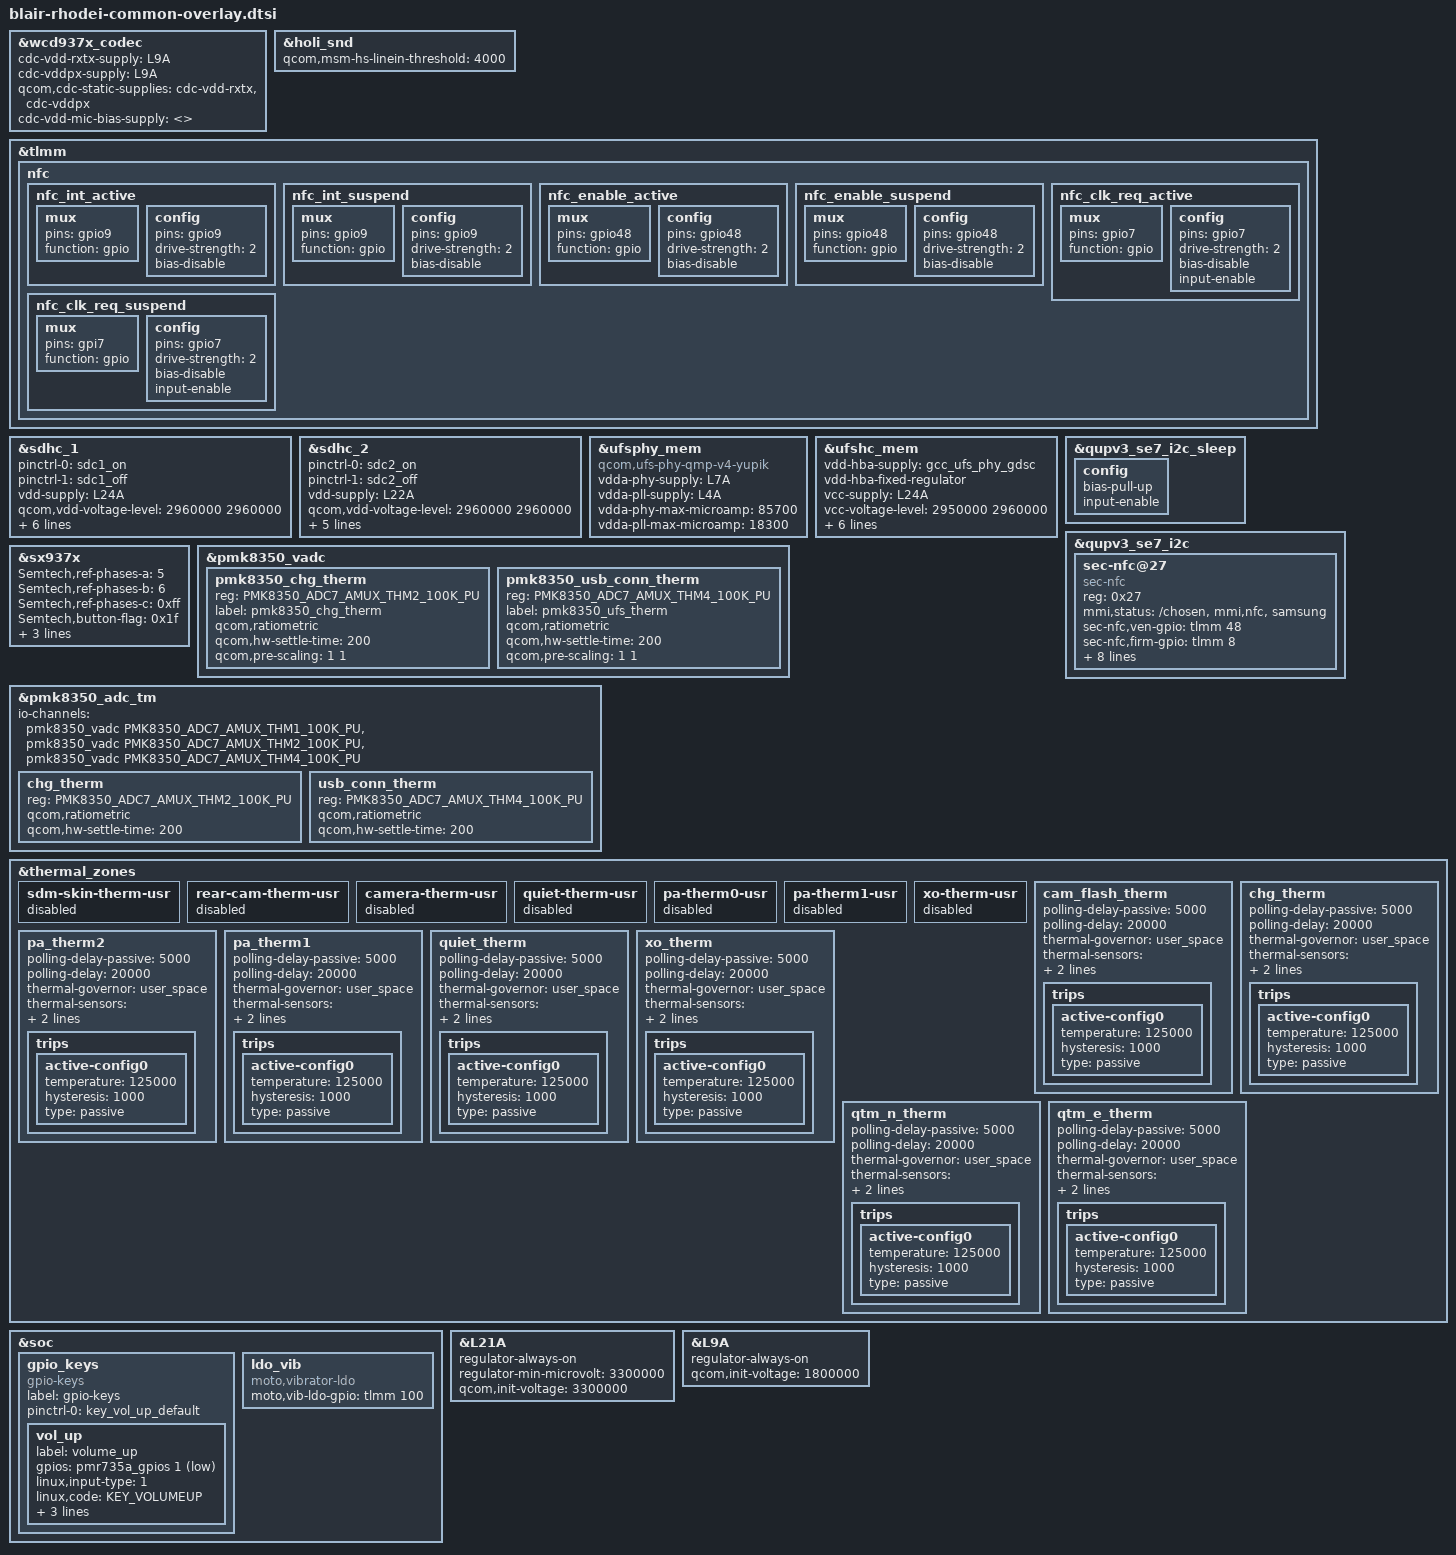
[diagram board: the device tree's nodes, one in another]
/* Copyright (c) 2021, The Linux Foundation. All rights reserved.
 *
 * This program is free software; you can redistribute it and/or modify
 * it under the terms of the GNU General Public License version 2 and
 * only version 2 as published by the Free Software Foundation.
 *
 * This program is distributed in the hope that it will be useful,
 * but WITHOUT ANY WARRANTY; without even the implied warranty of
 * MERCHANTABILITY or FITNESS FOR A PARTICULAR PURPOSE.  See the
 * GNU General Public License for more details.
 */
#include "blair-nopmi-moto-common-overlay.dtsi"

#include "holi-audio-wcd9370-aw882xx-acf-dual-overlay.dtsi"
#include <dt-bindings/gpio/gpio.h>
#include <dt-bindings/input/linux-event-codes.h>
#include "holi-pmic-overlay-pm6125.dtsi"
#include "holi-thermal-overlay-pm6125.dtsi"
#include "display/holi-sde-display-mtp-pm6125.dtsi"
#include "display/blair-sde-display-mtp.dtsi"
#include "rhodei-fps-overlay.dtsi"
#include "rhodei-display.dtsi"
#include "rhodei-touchscreen.dtsi"
#include "camera-legacy/rhodei/blair-camera-sensor-mot-rhodei-overlay.dtsi"
#include "rhodei-wl2868c.dtsi"
#include "discrete_charging_rhodei.dtsi"
#include "moto_therm_sys_temp.dtsi"

&wcd937x_codec {
	cdc-vdd-rxtx-supply = <&L9A>;
	cdc-vddpx-supply = <&L9A>;
	qcom,cdc-static-supplies = "cdc-vdd-rxtx",
				   "cdc-vddpx";
	/*
	 * Overriding cdc-vdd-mic-bias-supply to dummy value
	 * to avoid compilation errors as BOB is not definied
	 * for pm6125
	 */
	cdc-vdd-mic-bias-supply = <>;
};

&holi_snd {
	qcom,msm-hs-linein-threshold = <4000>;
};

&tlmm {
	nfc {
		nfc_int_active: nfc_int_active {
			/* active state */
			mux {
				/* GPIO 9: NFC Read Interrupt */
				pins = "gpio9";
				function = "gpio";
			};

			config {
				pins = "gpio9";
				drive-strength = <2>; /* 2 MA */
				bias-disable;
			};
		};

		nfc_int_suspend: nfc_int_suspend {
			/* sleep state */
			mux {
				/* GPIO 9: NFC Read Interrupt */
				pins = "gpio9";
				function = "gpio";
			};

			config {
				pins = "gpio9";
				drive-strength = <2>; /* 2 MA */
				bias-disable;
			};
		};

		nfc_enable_active: nfc_enable_active {
			mux {
				pins = "gpio48";
				function = "gpio";
			};

			config {
				pins = "gpio48";
				drive-strength = <2>; /* 2 MA */
				bias-disable;
			};
		};

		nfc_enable_suspend: nfc_enable_suspend {
			mux {
				pins = "gpio48";
				function = "gpio";
			};

			config {
				pins = "gpio48";
				drive-strength = <2>; /* 2 MA */
				bias-disable;
			};
		};


		nfc_clk_req_active: nfc_clk_req_active {
			/* active state */
			mux {
				/* GPIO 7: NFC CLK Req*/
				pins = "gpio7";
				function = "gpio";
			};

			config {
				pins = "gpio7";
				drive-strength = <2>; /* 2 MA */
				bias-disable;
				input-enable;
			};
		};

		nfc_clk_req_suspend: nfc_clk_req_suspend {
			/* sleep state */
			mux {
				/* GPIO 7: NFC CLK Req */
				pins = "gpi7";
				function = "gpio";
			};

			config {
				pins = "gpio7";
				drive-strength = <2>; /* 2 MA */
				bias-disable;
				input-enable;
			};
		};
	};
};

/* Dummy LDO reference */
&sdhc_1 {
	status = "ok";

	pinctrl-names = "default", "sleep";
	pinctrl-0 = <&sdc1_on>;
	pinctrl-1 = <&sdc1_off>;

	vdd-supply = <&L24A>;
	qcom,vdd-voltage-level = <2960000 2960000>;
	qcom,vdd-current-level = <0 570000>;

	vdd-io-supply = <&L11A>;
	qcom,vdd-io-always-on;
	qcom,vdd-io-lpm-sup;
	qcom,vdd-io-voltage-level = <1800000 1800000>;
	qcom,vdd-io-current-level = <0 325000>;
};

&sdhc_2 {
	status = "ok";

	pinctrl-names = "default", "sleep";
	pinctrl-0 = <&sdc2_on>;
	pinctrl-1 = <&sdc2_off>;

	vdd-supply = <&L22A>;
	qcom,vdd-voltage-level = <2960000 2960000>;
	qcom,vdd-current-level = <0 800000>;

	vdd-io-supply = <&L5A>;
	qcom,vdd-io-voltage-level = <1800000 2960000>;
	qcom,vdd-io-current-level = <0 22000>;

	cd-gpios = <&tlmm 94 GPIO_ACTIVE_HIGH>;
};

&ufsphy_mem {
		compatible = "qcom,ufs-phy-qmp-v4-yupik";

		vdda-phy-supply = <&L7A>;
		vdda-pll-supply = <&L4A>;
		vdda-phy-max-microamp = <85700>;
		vdda-pll-max-microamp = <18300>;

		status = "ok";
};

&ufshc_mem {
		vdd-hba-supply = <&gcc_ufs_phy_gdsc>;
		vdd-hba-fixed-regulator;

		vcc-supply = <&L24A>;
		vcc-voltage-level = <2950000 2960000>;
		vcc-max-microamp = <800000>;

		vccq2-supply = <&L11A>;
		vccq2-max-microamp = <800000>;
		vccq2-voltage-level = <1800000 1800000>;

		qcom,vddp-ref-clk-supply = <&L4A>;
		qcom,vddp-ref-clk-max-microamp = <100>;

		status = "ok";
};

&qupv3_se7_i2c_sleep {
    config {
        /delete-property/ bias-disable;
        bias-pull-up;
        input-enable;
    };
};

&qupv3_se7_i2c {
	status = "ok";
	#address-cells = <1>;
	#size-cells = <0>;
	sec-nfc@27 {
		compatible = "sec-nfc";
		reg = <0x27>;
		mmi,status = "/chosen", "mmi,nfc", "samsung";
		sec-nfc,ven-gpio = <&tlmm 48 0x00>;
		sec-nfc,firm-gpio = <&tlmm 8 0x00>;
		sec-nfc,irq-gpio = <&tlmm 9 0x00>;
		sec-nfc,clk_req-gpio = <&tlmm 7 0x00>;
		interrupt-parent = <&tlmm>;
		interrupts = <9 0>;
		interrupt-names = "nfc_irq";
		pinctrl-names = "nfc_active", "nfc_suspend";
		pinctrl-0 = <&nfc_int_active &nfc_enable_active &nfc_clk_req_active>;
		pinctrl-1 = <&nfc_int_suspend &nfc_enable_suspend &nfc_clk_req_suspend>;
	};
};

&sx937x {
		/*use PH5/6 as the reference sensor
		set it to 0xff if the ref-phases-x is not used*/
		Semtech,ref-phases-a = <5>;
		Semtech,ref-phases-b = <6>;
		Semtech,ref-phases-c = <0xff>;
		Semtech,button-flag = <0x1f>;
		Semtech,reg-num = <61>;
		Semtech,reg-init = <
			0x8024 0x7F00
			0x4004 0x70
			0x4008 0x8
			0x8020 0x32
			0x8028 0x8A6
			0x8034 0x88E
			0x8040 0x8A6
			0x804C 0x88E
			0x8058 0x88E
			0x8064 0x88E
			0x8070 0x88E
			0x807C 0x88E
			0x8030 0xFFD9FF
			0x803C 0xBFF9FF
			0x8048 0xFFF9FD
			0x8054 0xFEF9FF
			0x8060 0xF7F9FF
			0x806C 0xFFF97F
			0x8078 0xFFF9EF
			0x8084 0xBFF9FF
			0x8098 0x693E
			0x80B8 0x3131
			0x80D8 0x6833
			0x80F8 0x2929
			0x8118 0x4C4C
			0x8138 0x8E
			0x8158 0x8E
			0x8178 0x5A40
			0x80A0 0x22220001
			0x80C0 0x1F1F0001
			0x80E0 0x48540002
			0x8100 0x1D1D001A
			0x8120 0x1A1A0002
			0x8188 0x8000015
			0x818C 0x8000016
			0x8190 0x10
			0x8194 0x12
			0x8090 0x64B45000
			0x80B0 0x3CD05000
			0x80D0 0x32D87000
			0x80F0 0x3CD45000
			0x8110 0x2CD87000
			0x8130 0x54AC5000
			0x8150 0x54AC5000
			0x8170 0x54AC5000
			0x8088 0x300000
			0x80A8 0x300000
			0x80C8 0x300000
			0x80E8 0x300000
			0x8108 0x300000
			0x8128 0x600000
			0x8148 0x600000
			0x8168 0x300000
			0x808C 0x60200030
			0x80AC 0x60200030
			0x80CC 0x60200018
			0x80EC 0x60200030
			0x810C 0x60200018
			0x812C 0x60200030
			0x814C 0x60200030
			0x816C 0x60200030
		>;

		status = "ok";
};

&pmk8350_vadc {
	pmk8350_chg_therm {
		reg = <PMK8350_ADC7_AMUX_THM2_100K_PU>;
		label = "pmk8350_chg_therm";
		qcom,ratiometric;
		qcom,hw-settle-time = <200>;
		qcom,pre-scaling = <1 1>;
	};

	pmk8350_usb_conn_therm {
		reg = <PMK8350_ADC7_AMUX_THM4_100K_PU>;
		label = "pmk8350_ufs_therm";
		qcom,ratiometric;
		qcom,hw-settle-time = <200>;
		qcom,pre-scaling = <1 1>;
	};
};

&pmk8350_adc_tm {
	io-channels = <&pmk8350_vadc PMK8350_ADC7_AMUX_THM1_100K_PU>,
			<&pmk8350_vadc PMK8350_ADC7_AMUX_THM2_100K_PU>,
			<&pmk8350_vadc PMK8350_ADC7_AMUX_THM4_100K_PU>;

	chg_therm {
		reg = <PMK8350_ADC7_AMUX_THM2_100K_PU>;
		qcom,ratiometric;
		qcom,hw-settle-time = <200>;
	};
	usb_conn_therm {
		reg = <PMK8350_ADC7_AMUX_THM4_100K_PU>;
		qcom,ratiometric;
		qcom,hw-settle-time = <200>;
	};
};

&thermal_zones {
	sdm-skin-therm-usr {
		status = "disabled";
	};
	rear-cam-therm-usr {
		status = "disabled";
	};
	camera-therm-usr {
		status = "disabled";
	};
	quiet-therm-usr {
		status = "disabled";
	};
	pa-therm0-usr {
		status = "disabled";
	};
	pa-therm1-usr {
		status = "disabled";
	};
	xo-therm-usr {
		status = "disabled";
	};

	cam_flash_therm {
		polling-delay-passive = <5000>;
		polling-delay = <20000>;
		thermal-governor = "user_space";
		thermal-sensors = <&pm6125_adc_tm_iio ADC5_GPIO1_100K_PU>;
		wake-capable-sensor;
		trips {
			active-config0 {
				temperature = <125000>;
				hysteresis = <1000>;
				type = "passive";
			};
		};
	};

	chg_therm {
		polling-delay-passive = <5000>;
		polling-delay = <20000>;
		thermal-governor = "user_space";
		thermal-sensors = <&pm6125_adc_tm_iio ADC5_GPIO2_100K_PU>;
		wake-capable-sensor;
		trips {
			active-config0 {
				temperature = <125000>;
				hysteresis = <1000>;
				type = "passive";
			};
		};
	};

	pa_therm2 {
		polling-delay-passive = <5000>;
		polling-delay = <20000>;
		thermal-governor = "user_space";
		thermal-sensors = <&pm6125_adc_tm ADC5_GPIO4_100K_PU>;
		wake-capable-sensor;
		trips {
			active-config0 {
				temperature = <125000>;
				hysteresis = <1000>;
				type = "passive";
			};
		};
	};

	pa_therm1 {
		polling-delay-passive = <5000>;
		polling-delay = <20000>;
		thermal-governor = "user_space";
		thermal-sensors = <&pm6125_adc_tm ADC5_AMUX_THM1_100K_PU>;
		wake-capable-sensor;
		trips {
			active-config0 {
				temperature = <125000>;
				hysteresis = <1000>;
				type = "passive";
			};
		};
	};

	quiet_therm {
		polling-delay-passive = <5000>;
		polling-delay = <20000>;
		thermal-governor = "user_space";
		thermal-sensors = <&pm6125_adc_tm ADC5_AMUX_THM2_100K_PU>;
		wake-capable-sensor;
		trips {
			active-config0 {
				temperature = <125000>;
				hysteresis = <1000>;
				type = "passive";
			};
		};
	};

	xo_therm {
		polling-delay-passive = <5000>;
		polling-delay = <20000>;
		thermal-governor = "user_space";
		thermal-sensors = <&pmk8350_adc_tm PMK8350_ADC7_AMUX_THM1_100K_PU>;
		wake-capable-sensor;
		trips {
			active-config0 {
				temperature = <125000>;
				hysteresis = <1000>;
				type = "passive";
			};
		};
	};

	qtm_n_therm {
		polling-delay-passive = <5000>;
		polling-delay = <20000>;
		thermal-governor = "user_space";
		thermal-sensors = <&pmk8350_adc_tm PMK8350_ADC7_AMUX_THM2_100K_PU>;
		wake-capable-sensor;
		trips {
			active-config0 {
				temperature = <125000>;
				hysteresis = <1000>;
				type = "passive";
			};
		};
	};

	qtm_e_therm {
		polling-delay-passive = <5000>;
		polling-delay = <20000>;
		thermal-governor = "user_space";
		thermal-sensors = <&pmk8350_adc_tm PMK8350_ADC7_AMUX_THM4_100K_PU>;
		wake-capable-sensor;
		trips {
			active-config0 {
				temperature = <125000>;
				hysteresis = <1000>;
				type = "passive";
			};
		};
	};

};

&soc {
	gpio_keys {
		compatible = "gpio-keys";
		label = "gpio-keys";

		pinctrl-names = "default";
		pinctrl-0 = <&key_vol_up_default>;

		vol_up {
			label = "volume_up";
			gpios = <&pmr735a_gpios 1 GPIO_ACTIVE_LOW>;
			linux,input-type = <1>;
			linux,code = <KEY_VOLUMEUP>;
			gpio-key,wakeup;
			debounce-interval = <15>;
			linux,can-disable;
		};
	};

	ldo_vib {
		compatible = "moto,vibrator-ldo";
		moto,vib-ldo-gpio = <&tlmm 100 0x0>;
		status = "ok";
	};
};

&L21A {
	regulator-always-on; //typec and LEDA power
	regulator-min-microvolt = <3300000>;
	qcom,init-voltage = <3300000>;
	status = "okay";
};

&L9A {
	regulator-always-on; //SAR interrupt power
	qcom,init-voltage = <1800000>;
	status = "okay";
};
